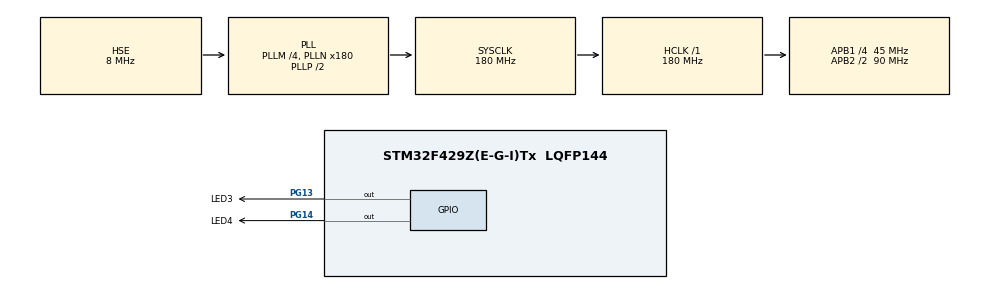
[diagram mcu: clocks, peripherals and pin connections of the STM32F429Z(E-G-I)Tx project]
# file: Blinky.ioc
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Mcu.Family=STM32F4
Mcu.Name=STM32F429Z(E-G-I)Tx
Mcu.Package=LQFP144
NVIC.PriorityGroup=NVIC_PRIORITYGROUP_4
PA13.Mode=Serial_Wire
PA13.Signal=SYS_JTMS-SWDIO
PA14.Mode=Serial_Wire
PA14.Signal=SYS_JTCK-SWCLK
PG13.GPIO_Label=LED3
PG13.Signal=GPIO_Output
PG14.GPIO_Label=LED4
PG14.Signal=GPIO_Output
PH0/OSC_IN.Mode=HSE-External-Oscillator
PH0/OSC_IN.Signal=RCC_OSC_IN
PH1/OSC_OUT.Mode=HSE-External-Oscillator
PH1/OSC_OUT.Signal=RCC_OSC_OUT
ProjectManager.HeapSize=0x200
ProjectManager.StackSize=0x400
ProjectManager.TargetToolchain=SW4STM32
RCC.48MHZClocksFreq_Value=90000000
RCC.AHBFreq_Value=180000000
RCC.APB1CLKDivider=RCC_HCLK_DIV4
RCC.APB1Freq_Value=45000000
RCC.APB1TimFreq_Value=90000000
RCC.APB2CLKDivider=RCC_HCLK_DIV2
RCC.APB2Freq_Value=90000000
RCC.APB2TimFreq_Value=180000000
RCC.CortexFreq_Value=180000000
RCC.HCLKFreq_Value=180000000
RCC.HSE_VALUE=8000000
RCC.HSI_VALUE=16000000
RCC.LSE_VALUE=32768
RCC.PLLM=4
RCC.PLLN=180
RCC.PLLSourceVirtual=RCC_PLLSOURCE_HSE
RCC.SYSCLKFreq_VALUE=180000000
RCC.SYSCLKSource=RCC_SYSCLKSOURCE_PLLCLK
RCC.VCOOutputFreq_Value=360000000
board=Blinky

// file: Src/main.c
/**
  ******************************************************************************
  * File Name          : main.c
  * Description        : Main program body
  ******************************************************************************
  ** This notice applies to any and all portions of this file
  * that are not between comment pairs USER CODE BEGIN and
  * USER CODE END. Other portions of this file, whether
  * inserted by the user or by software development tools
  * are owned by their respective copyright owners.
  *
  * COPYRIGHT(c) 2018 STMicroelectronics
  *
  * Redistribution and use in source and binary forms, with or without modification,
  * are permitted provided that the following conditions are met:
  *   1. Redistributions of source code must retain the above copyright notice,
  *      this list of conditions and the following disclaimer.
  *   2. Redistributions in binary form must reproduce the above copyright notice,
  *      this list of conditions and the following disclaimer in the documentation
  *      and/or other materials provided with the distribution.
  *   3. Neither the name of STMicroelectronics nor the names of its contributors
  *      may be used to endorse or promote products derived from this software
  *      without specific prior written permission.
  *
  * THIS SOFTWARE IS PROVIDED BY THE COPYRIGHT HOLDERS AND CONTRIBUTORS "AS IS"
  * AND ANY EXPRESS OR IMPLIED WARRANTIES, INCLUDING, BUT NOT LIMITED TO, THE
  * IMPLIED WARRANTIES OF MERCHANTABILITY AND FITNESS FOR A PARTICULAR PURPOSE ARE
  * DISCLAIMED. IN NO EVENT SHALL THE COPYRIGHT HOLDER OR CONTRIBUTORS BE LIABLE
  * FOR ANY DIRECT, INDIRECT, INCIDENTAL, SPECIAL, EXEMPLARY, OR CONSEQUENTIAL
  * DAMAGES (INCLUDING, BUT NOT LIMITED TO, PROCUREMENT OF SUBSTITUTE GOODS OR
  * SERVICES; LOSS OF USE, DATA, OR PROFITS; OR BUSINESS INTERRUPTION) HOWEVER
  * CAUSED AND ON ANY THEORY OF LIABILITY, WHETHER IN CONTRACT, STRICT LIABILITY,
  * OR TORT (INCLUDING NEGLIGENCE OR OTHERWISE) ARISING IN ANY WAY OUT OF THE USE
  * OF THIS SOFTWARE, EVEN IF ADVISED OF THE POSSIBILITY OF SUCH DAMAGE.
  *
  ******************************************************************************
  */
#include "main.h"
#include "stm32f4xx_hal.h"

/* USER CODE BEGIN PV */
/* Private variables ---------------------------------------------------------*/

/* USER CODE END PV */

void SystemClock_Config(void);
static void MX_GPIO_Init(void);

/* USER CODE BEGIN PFP */
/* Private function prototypes -----------------------------------------------*/

/* USER CODE END PFP */

/* USER CODE BEGIN 0 */

// GPIO mode is in bit 0 and 1
typedef enum{
	GPIO_INPUT = 0,
	GPIO_OUTPUT,
	GPIO_ALT_FUNC,
	GPIO_ANALOG
}	GpioMode;

// GPIO output driver type is in bit 2
typedef enum{
	GPIO_PUSH_PULL = 0,
	GPIO_OPEN_DRAIN = 1 << 2,	// use bit 3 bcz bit 1 and bit 2 used in GpioMode
}	GpioDriverType;

// GPIO output speed is in bits 3 and 4
typedef enum{
	GPIO_LOW_SPEED = 0,
	GPIO_MED_SPEED = 1 << 3,
	GPIO_HI_SPEED = 2 << 3,
	GPIO_VERY_HI_SPEED = 3 << 3,
}	GpioOutputSpeed;

// GPIO pull type is in bits 5 and 6
typedef enum{
	GPIO_NO_PULL = 0,
	GPIO_PULL_UP = 1 << 5,
	GPIO_PULL_DOWN = 2 << 5,
}	GpioPullType;

typedef enum{
	GPIOPin0  = 0x0001,
	GPIOPin1  = 0x0002,
	GPIOPin2  = 0x0004,
	GPIOPin3  = 0x0008,
	GPIOPin4  = 0x0010,
	GPIOPin5  = 0x0020,
	GPIOPin6  = 0x0040,
	GPIOPin7  = 0x0080,
	GPIOPin8  = 0x0100,
	GPIOPin9  = 0x0200,
	GPIOPin10 = 0x0400,
	GPIOPin11 = 0x0800,
	GPIOPin12 = 0x1000,
	GPIOPin13 = 0x2000,
	GPIOPin14 = 0x4000,
	GPIOPin15 = 0x8000,
}	GPIOPin;

typedef volatile uint32_t IORegister ;

typedef struct GPIORegs GPIORegs;
struct GPIORegs {
	IORegister mode;
	IORegister driverType;
	IORegister outSpeed;
	IORegister pullType;
	IORegister inData;
	IORegister outData;
	IORegister outBits;
	IORegister pinLock;
	IORegister altFuncLow;
	IORegister altFuncHi;
};

#define GPIOA	((GPIORegs *)0x40020000)
#define GPIOB	((GPIORegs *)0x40020400)
#define GPIOC	((GPIORegs *)0x40020800)
#define GPIOD	((GPIORegs *)0x40020c00)
#define GPIOE	((GPIORegs *)0x40021000)
#define GPIOF	((GPIORegs *)0x40021400)
#define GPIOG	((GPIORegs *)0x40021800)
#define GPIOH	((GPIORegs *)0x40021c00)
#define GPIOI	((GPIORegs *)0x40022000)
#define GPIOJ	((GPIORegs *)0x40022400)
#define GPIOK	((GPIORegs *)0x40022800)

/* *
 * To configure the GPIO pin.
 *
 * Input:
 * 	 port			the port to configure
 * 	 pin			the pin to configure
 * 	 configuration	the configuration setting for the pin
 *	 	 	 	 	[1:0] Mode
 *	 	 	 	 	[2:2] Output type
 *	 	 	 	 	[4:3] Output speed
 *	 	 	 	 	[6:5] Pull type
 *
 * 	 E.g. :
 * 	 	gpioConfigurePin (GPIOA, GPIOPin0, GPIO_OUTPUT | 		\
 * 	 									   GPIO_OPEN_DRAIN |	\
 * 	 									   GPIO_HI_SPEED|		\
 * 	 									   GPIO_NO_PULL);
 * */

void GPIOConfigurePin(GPIORegs *port, GPIOPin pins, int configuration){
	uint32_t i, pinMask, tempMask;
	uint32_t mode;
	uint32_t driver;
	uint32_t outSpeed;
	uint32_t pullType;

	pinMask = 0x1;
	mode = configuration & 0x3;
	driver = (configuration & 0x4) >> 2;
	outSpeed = (configuration & 0x18) >> 3;
	pullType = (configuration & 0x60) >> 5;

	for(i = 0; i <16 ; i++){
		tempMask = pinMask & pins;
		if(tempMask == 1){
			port->mode &= ~(3 << (i * 2));
			port->mode |= mode << (i * 2);

			port->driverType &= ~(1 << (i * 1)) ;
			port->driverType |= driver << (i * 1);;

			port->outSpeed &= ~(3 << (i * 2));
			port->outSpeed |= outSpeed  << (i * 2);

			port->pullType &= ~(3 << (i * 2));
			port->pullType |= pullType << (i * 2);

		}
		pinMask = pinMask << 1;
	}

}
/* USER CODE END 0 */

/* USER CODE END 0 */

int main(void)
{

  /* MCU Configuration----------------------------------------------------------*/

  /* Reset of all peripherals, Initializes the Flash interface and the Systick. */
    HAL_Init();

  /* Configure the system clock */
  SystemClock_Config();

  /* Initialize all configured peripherals */
  MX_GPIO_Init();

  /* Infinite loop */
  /* USER CODE BEGIN WHILE */
  while (1)
  {
	  GPIOConfigurePin (GPIOA, GPIOPin0, GPIO_OUTPUT|GPIO_OPEN_DRAIN|GPIO_HI_SPEED|GPIO_NO_PULL);
	  /*
	  HAL_GPIO_WritePin(GPIOG, LED3_Pin, GPIO_PIN_RESET);
	  HAL_GPIO_WritePin(GPIOG, LED4_Pin, GPIO_PIN_SET);
	  HAL_Delay(250);
	  HAL_GPIO_WritePin(GPIOG, LED3_Pin, GPIO_PIN_SET);
	  HAL_GPIO_WritePin(GPIOG, LED4_Pin, GPIO_PIN_RESET);
	  HAL_Delay(250);
	  */
  /* USER CODE END WHILE */

  }

}

/** System Clock Configuration
*/
void SystemClock_Config(void)
{

  RCC_OscInitTypeDef RCC_OscInitStruct;
  RCC_ClkInitTypeDef RCC_ClkInitStruct;

    /**Configure the main internal regulator output voltage
    */
  __HAL_RCC_PWR_CLK_ENABLE();

  __HAL_PWR_VOLTAGESCALING_CONFIG(PWR_REGULATOR_VOLTAGE_SCALE1);

    /**Initializes the CPU, AHB and APB busses clocks
    */
  RCC_OscInitStruct.OscillatorType = RCC_OSCILLATORTYPE_HSE;
  RCC_OscInitStruct.HSEState = RCC_HSE_ON;
  RCC_OscInitStruct.PLL.PLLState = RCC_PLL_ON;
  RCC_OscInitStruct.PLL.PLLSource = RCC_PLLSOURCE_HSE;
  RCC_OscInitStruct.PLL.PLLM = 4;
  RCC_OscInitStruct.PLL.PLLN = 180;
  RCC_OscInitStruct.PLL.PLLP = RCC_PLLP_DIV2;
  RCC_OscInitStruct.PLL.PLLQ = 4;
  if (HAL_RCC_OscConfig(&RCC_OscInitStruct) != HAL_OK)
  {
    _Error_Handler(__FILE__, __LINE__);
  }

    /**Activate the Over-Drive mode
    */
  if (HAL_PWREx_EnableOverDrive() != HAL_OK)
  {
    _Error_Handler(__FILE__, __LINE__);
  }

    /**Initializes the CPU, AHB and APB busses clocks
    */
  RCC_ClkInitStruct.ClockType = RCC_CLOCKTYPE_HCLK|RCC_CLOCKTYPE_SYSCLK
                              |RCC_CLOCKTYPE_PCLK1|RCC_CLOCKTYPE_PCLK2;
  RCC_ClkInitStruct.SYSCLKSource = RCC_SYSCLKSOURCE_PLLCLK;
  RCC_ClkInitStruct.AHBCLKDivider = RCC_SYSCLK_DIV1;
  RCC_ClkInitStruct.APB1CLKDivider = RCC_HCLK_DIV4;
  RCC_ClkInitStruct.APB2CLKDivider = RCC_HCLK_DIV2;

  if (HAL_RCC_ClockConfig(&RCC_ClkInitStruct, FLASH_LATENCY_5) != HAL_OK)
  {
    _Error_Handler(__FILE__, __LINE__);
  }

    /**Configure the Systick interrupt time
    */
  HAL_SYSTICK_Config(HAL_RCC_GetHCLKFreq()/1000);

    /**Configure the Systick
    */
  HAL_SYSTICK_CLKSourceConfig(SYSTICK_CLKSOURCE_HCLK);

  /* SysTick_IRQn interrupt configuration */
  HAL_NVIC_SetPriority(SysTick_IRQn, 0, 0);
}

/** Configure pins as
        * Analog
        * Input
        * Output
        * EVENT_OUT
        * EXTI
*/
static void MX_GPIO_Init(void)
{

  GPIO_InitTypeDef GPIO_InitStruct;

  /* GPIO Ports Clock Enable */
  __HAL_RCC_GPIOH_CLK_ENABLE();
  __HAL_RCC_GPIOA_CLK_ENABLE();
  __HAL_RCC_GPIOG_CLK_ENABLE();

  /*Configure GPIO pin Output Level */
  HAL_GPIO_WritePin(GPIOG, LED3_Pin|LED4_Pin, GPIO_PIN_RESET);

  /*Configure GPIO pins : LED3_Pin LED4_Pin */
  GPIO_InitStruct.Pin = LED3_Pin|LED4_Pin;
  GPIO_InitStruct.Mode = GPIO_MODE_OUTPUT_PP;
  GPIO_InitStruct.Pull = GPIO_NOPULL;
  GPIO_InitStruct.Speed = GPIO_SPEED_FREQ_LOW;
  HAL_GPIO_Init(GPIOG, &GPIO_InitStruct);

}

void _Error_Handler(char * file, int line)
{
  while(1)
  {
  }
}

/************************ (C) COPYRIGHT STMicroelectronics *****END OF FILE****/
